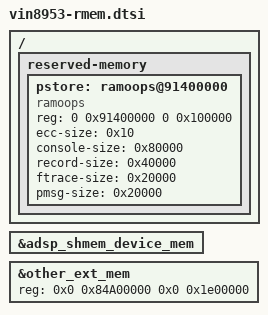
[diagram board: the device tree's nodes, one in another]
/ {
	reserved-memory {
		pstore: ramoops@91400000 {
			compatible = "ramoops";
			reg = <0 0x91400000 0 0x100000>;
			ecc-size = <0x10>;
			console-size = <0x80000>;
			record-size = <0x40000>;
			ftrace-size = <0x20000>;
			pmsg-size = <0x20000>;
		};
	};
};

&adsp_shmem_device_mem {
	/delete-property/ label;
};

&other_ext_mem {
	reg = <0x0 0x84A00000 0x0 0x1e00000>;
};
